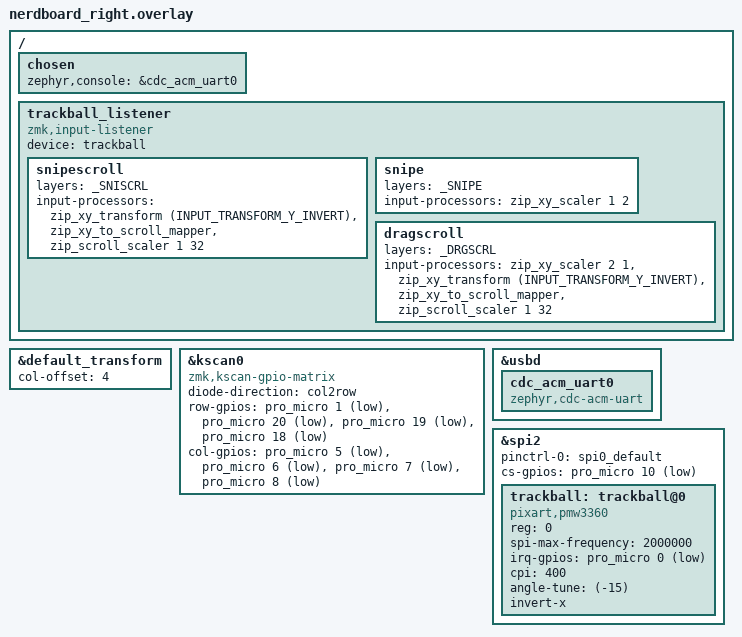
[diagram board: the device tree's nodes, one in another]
#include "nerdboard.overlay"
#include <input/processors.dtsi>
#include <zephyr/dt-bindings/input/input-event-codes.h>
#include <dt-bindings/zmk/input_transform.h>

&default_transform {
    col-offset = <4>;
};

&kscan0 {
    compatible = "zmk,kscan-gpio-matrix";
    diode-direction = "col2row";

    row-gpios
        = <&pro_micro  1 (GPIO_ACTIVE_LOW | GPIO_PULL_UP)>
        , <&pro_micro 20 (GPIO_ACTIVE_LOW | GPIO_PULL_UP)>
        , <&pro_micro 19 (GPIO_ACTIVE_LOW | GPIO_PULL_UP)>
        , <&pro_micro 18 (GPIO_ACTIVE_LOW | GPIO_PULL_UP)>
        ;

    col-gpios
        = <&pro_micro 5 GPIO_ACTIVE_LOW>
        , <&pro_micro 6 GPIO_ACTIVE_LOW>
        , <&pro_micro 7 GPIO_ACTIVE_LOW>
        , <&pro_micro 8 GPIO_ACTIVE_LOW>
        ;
};

/ {
    chosen {
        zephyr,console = &cdc_acm_uart0;
    };
};

&usbd {
    cdc_acm_uart0: cdc_acm_uart0 {
        compatible = "zephyr,cdc-acm-uart";
    };
};

&spi2 {
    status = "okay";
    pinctrl-0 = <&spi0_default>;
    pinctrl-names = "default";
    cs-gpios = <&pro_micro 10 GPIO_ACTIVE_LOW>;

    trackball: trackball@0 {
        compatible = "pixart,pmw3360";
        status = "okay";
        reg = <0>;
        spi-max-frequency = <2000000>;

        irq-gpios = <&pro_micro 0 (GPIO_ACTIVE_LOW | GPIO_PULL_UP)>;

        cpi = <400>;
        angle-tune = <(-15)>;
        invert-x;
    };
};

// Keep in sync with layer indexes in nerdboard.keymap
#define _SNIPE   6
#define _DRGSCRL 7
#define _SNISCRL 8

/ {
    trackball_listener: trackball_listener {
        compatible = "zmk,input-listener";
        device = <&trackball>;

        snipescroll {
            layers = <_SNISCRL>;
            input-processors = <
                &zip_xy_transform (INPUT_TRANSFORM_Y_INVERT)
                &zip_xy_to_scroll_mapper
                &zip_scroll_scaler 1 32
            >;
        };

        snipe {
            layers = <_SNIPE>;
            input-processors = <
                &zip_xy_scaler 1 2
            >;
        };

        dragscroll {
            layers = <_DRGSCRL>;
            input-processors = <
                &zip_xy_scaler 2 1
                &zip_xy_transform (INPUT_TRANSFORM_Y_INVERT)
                &zip_xy_to_scroll_mapper
                &zip_scroll_scaler 1 32
            >;
        };
    };
};


